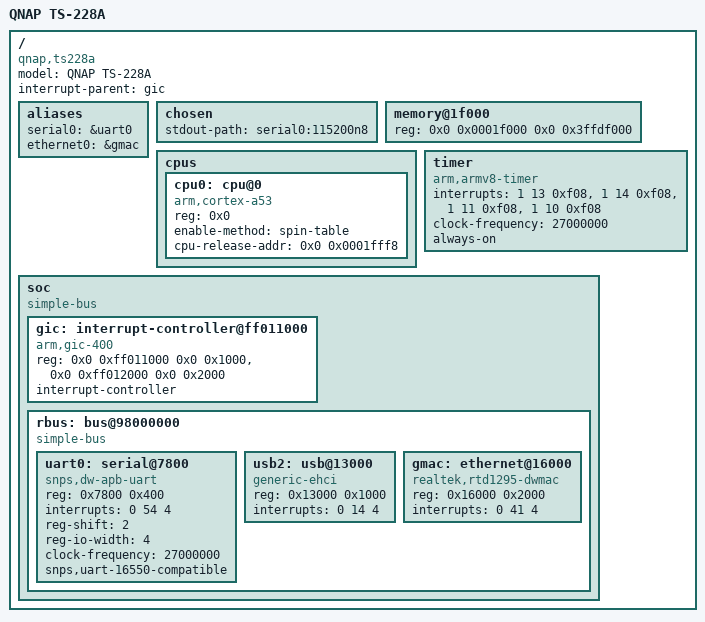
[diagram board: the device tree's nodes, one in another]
/dts-v1/;

/ {
    compatible = "qnap,ts228a", "realtek,rtd1295";
    model = "QNAP TS-228A";
    interrupt-parent = <&gic>;
    #address-cells = <2>;
    #size-cells = <2>;

    aliases {
        serial0 = &uart0;
        ethernet0 = &gmac;
    };

    chosen {
        stdout-path = "serial0:115200n8";
    };

    memory@1f000 {
        device_type = "memory";
        reg = <0x0 0x0001f000 0x0 0x3ffdf000>;
    };

    cpus {
        #address-cells = <1>;
        #size-cells = <0>;
        cpu0: cpu@0 {
            device_type = "cpu";
            compatible = "arm,cortex-a53";
            reg = <0x0>;
            enable-method = "spin-table";
            cpu-release-addr = <0x0 0x0001fff8>;
        };
    };

    /* UPDATED TIMER: Includes always-on property to stop systemd stalls */
    timer {
        compatible = "arm,armv8-timer";
        interrupts = <1 13 0xf08>, /* Phys Secure */
                     <1 14 0xf08>, /* Phys Non-Secure */
                     <1 11 0xf08>, /* Virt */
                     <1 10 0xf08>; /* Hyp */
        clock-frequency = <27000000>;
        always-on; /* Crucial for RTD1295 to prevent clock-drift stalls */
    };

    soc {
        compatible = "simple-bus";
        #address-cells = <2>;
        #size-cells = <2>;
        ranges;

        gic: interrupt-controller@ff011000 {
            compatible = "arm,gic-400";
            reg = <0x0 0xff011000 0x0 0x1000>,
                  <0x0 0xff012000 0x0 0x2000>;
            interrupt-controller;
            #interrupt-cells = <3>;
        };

        rbus: bus@98000000 {
            compatible = "simple-bus";
            #address-cells = <1>;
            #size-cells = <1>;
            ranges = <0x0 0x0 0x98000000 0x200000>;

            uart0: serial@7800 {
                compatible = "snps,dw-apb-uart";
                reg = <0x7800 0x400>;
                interrupts = <0 54 4>;
                reg-shift = <2>;
                reg-io-width = <4>;
                clock-frequency = <27000000>;
                snps,uart-16550-compatible; 
                status = "okay";
            };

            usb2: usb@13000 {
                compatible = "generic-ehci";
                reg = <0x13000 0x1000>;
                /* Based on your log, IRQ 14 is the hardware-wired value */
                interrupts = <0 14 4>; 
                status = "okay";
            };

            gmac: ethernet@16000 {
                compatible = "realtek,rtd1295-dwmac", "snps,dwmac-4.10a";
                reg = <0x16000 0x2000>;
                interrupts = <0 41 4>;
                interrupt-names = "macirq";
                status = "okay";
            };
        };
    };
};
